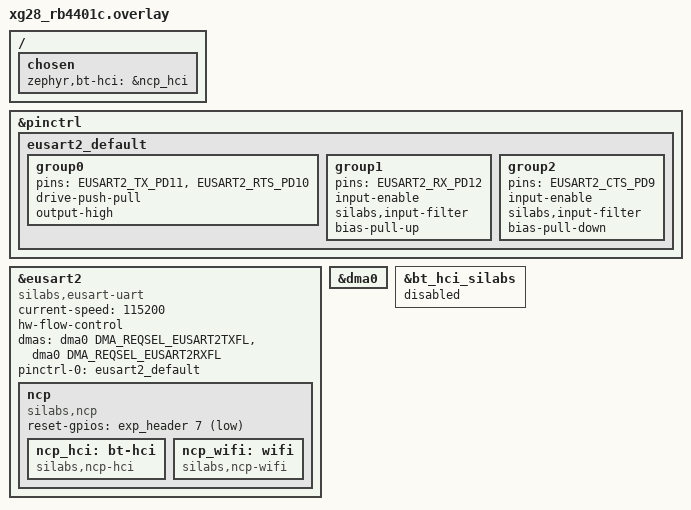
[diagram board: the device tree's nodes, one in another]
/*
 * Copyright (c) 2026 Silicon Laboratories Inc.
 * SPDX-License-Identifier: Apache-2.0
 */

/ {
	chosen {
		zephyr,bt-hci = &ncp_hci;
	};
};

&pinctrl {
	eusart2_default: eusart2_default {
		group0 {
			pins = <EUSART2_TX_PD11>,  /* P9 / EXP 12 */
			       <EUSART2_RTS_PD10>; /* P7 / EXP 10 */
			drive-push-pull;
			output-high;
		};

		group1 {
			pins = <EUSART2_RX_PD12>; /* P11 / EXP 14 */
			input-enable;
			silabs,input-filter;
			/* Keep RX idle high when nothing is connected */
			bias-pull-up;
		};

		group2 {
			pins = <EUSART2_CTS_PD9>; /* P5 / EXP 8 */
			input-enable;
			silabs,input-filter;
			/* Allow transmission when the co-processor does not drive RTS */
			bias-pull-down;
		};
	};
};

&eusart2 {
	compatible = "silabs,eusart-uart";
	current-speed = <115200>;
	hw-flow-control;
	dmas = <&dma0 DMA_REQSEL_EUSART2TXFL>,
	       <&dma0 DMA_REQSEL_EUSART2RXFL>;
	dma-names = "tx", "rx";
	pinctrl-0 = <&eusart2_default>;
	pinctrl-names = "default";
	status = "okay";

	ncp: ncp {
		compatible = "silabs,ncp";
		reset-gpios = <&exp_header 7 GPIO_ACTIVE_LOW>; /* P4 / EXP 7 / PA13 */

		ncp_hci: bt-hci {
			compatible = "silabs,ncp-hci";
		};

		ncp_wifi: wifi {
			compatible = "silabs,ncp-wifi";
		};
	};
};

&dma0 {
	status = "okay";
};

/* The Bluetooth controller is the one of the co-processor */
&bt_hci_silabs {
	status = "disabled";
};
